# STM32H747_CM7 register map
File version: 2.3
CPU: CM7 r0p1, little endian, MPU, FPU, 4 interrupt priority bits
Registers are 32-bit, read-write, reset 0x0 unless marked. A register's access mark holds for its fields unless they carry their own. Offsets are from the block's base; [hi:lo] are bit positions; lines under a group give offsets from that group; {n}, {i} and the like mark numbered series; 'fields as' and 'values as' point back to an identical list.

## FLASH — Embedded Flash Memory
Base 0x52002000
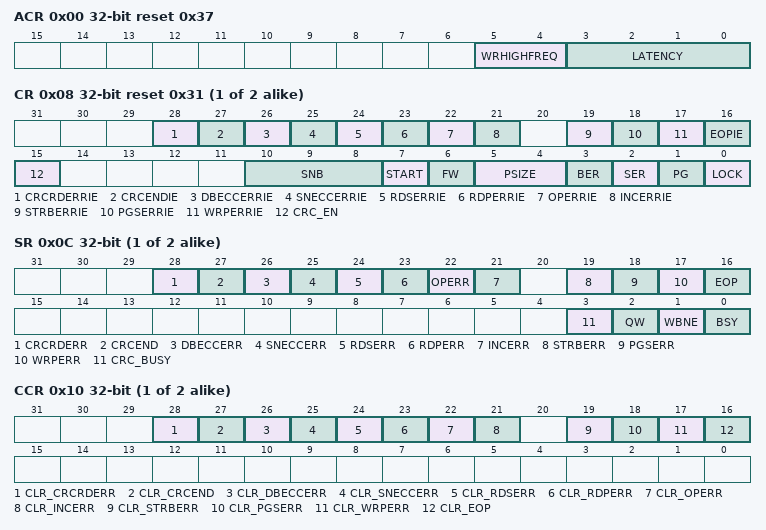
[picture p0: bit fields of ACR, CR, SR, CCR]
0x00 ACR access not given reset 0x37 — FLASH access control register
  [5:4] WRHIGHFREQ — Flash signal delay
  [3:0] LATENCY — Read latency
0x04 BANK{i} (i=1..2; step 0x100) group — Cluster BANK{i}, containing KEYR?, CR?, SR?, CCR?, PRAR_CUR?, PRAR_PRG?, SCAR_CUR?, SCAR_PRG?, WPSN_CUR?R, WPSN_PRG?R, CRCCR?, CRCSADD?R, CRCEADD?R, ECC_FA?R
  0x00 KEYR wo — FLASH key register for bank 1
    [31:0] KEY1R — Bank access configuration unlock key
  0x08 CR access not given reset 0x31 — FLASH control register for bank 1
    [28] CRCRDERRIE — Bank 1 CRC read error interrupt enable bit
    [27] CRCENDIE — Bank 1 CRC end of calculation interrupt enable bit
    [26] DBECCERRIE — Bank 1 ECC double detection error interrupt enable bit
    [25] SNECCERRIE — Bank 1 ECC single correction error interrupt enable bit
    [24] RDSERRIE — Bank 1 secure error interrupt enable bit
    [23] RDPERRIE — Bank 1 read protection error interrupt enable bit
    [22] OPERRIE — Bank 1 write
    [21] INCERRIE — Bank 1 inconsistency error interrupt enable bit
    [19] STRBERRIE — Bank 1 strobe error interrupt enable bit
    [18] PGSERRIE — Bank 1 programming sequence error interrupt enable bit
    [17] WRPERRIE — Bank 1 write protection error interrupt enable bit
    [16] EOPIE — Bank 1 end-of-program interrupt control bit
    [15] CRC_EN — Bank 1 CRC control bit
    [10:8] SNB — Bank 1 sector erase selection number
    [7] START — Bank 1 erase start control bit
    [6] FW — Bank 1 write forcing control bit
    [5:4] PSIZE — Bank 1 program size
    [3] BER — Bank 1 erase request
    [2] SER — Bank 1 sector erase request
    [1] PG — Bank 1 internal buffer control bit
    [0] LOCK — Bank 1 configuration lock bit
  0x0C SR access not given — FLASH status register for bank 1
    [28] CRCRDERR — Bank 1 CRC read error flag
    [27] CRCEND — Bank 1 CRC end of calculation flag
    [26] DBECCERR — Bank 1 ECC double detection error flag
    [25] SNECCERR — Bank 1 single correction error flag
    [24] RDSERR — Bank 1 secure error flag
    [23] RDPERR — Bank 1 read protection error flag
    [22] OPERR — Bank 1 write
    [21] INCERR — Bank 1 inconsistency error flag
    [19] STRBERR — Bank 1 strobe error flag
    [18] PGSERR — Bank 1 programming sequence error flag
    [17] WRPERR — Bank 1 write protection error flag
    [16] EOP — Bank 1 end-of-program flag
    [3] CRC_BUSY — Bank 1 CRC busy flag
    [2] QW — Bank 1 wait queue flag
    [1] WBNE — Bank 1 write buffer not empty flag
    [0] BSY — Bank 1 busy flag
  0x10 CCR access not given — FLASH clear control register for bank 1
    [28] CLR_CRCRDERR — Bank 1 CRCRDERR1 flag clear bit
    [27] CLR_CRCEND — Bank 1 CRCEND1 flag clear bit
    [26] CLR_DBECCERR — Bank 1 DBECCERR1 flag clear bit
    [25] CLR_SNECCERR — Bank 1 SNECCERR1 flag clear bit
    [24] CLR_RDSERR — Bank 1 RDSERR1 flag clear bit
    [23] CLR_RDPERR — Bank 1 RDPERR1 flag clear bit
    [22] CLR_OPERR — Bank 1 OPERR1 flag clear bit
    [21] CLR_INCERR — Bank 1 INCERR1 flag clear bit
    [19] CLR_STRBERR — Bank 1 STRBERR1 flag clear bit
    [18] CLR_PGSERR — Bank 1 PGSERR1 flag clear bit
    [17] CLR_WRPERR — Bank 1 WRPERR1 flag clear bit
    [16] CLR_EOP — Bank 1 EOP1 flag clear bit
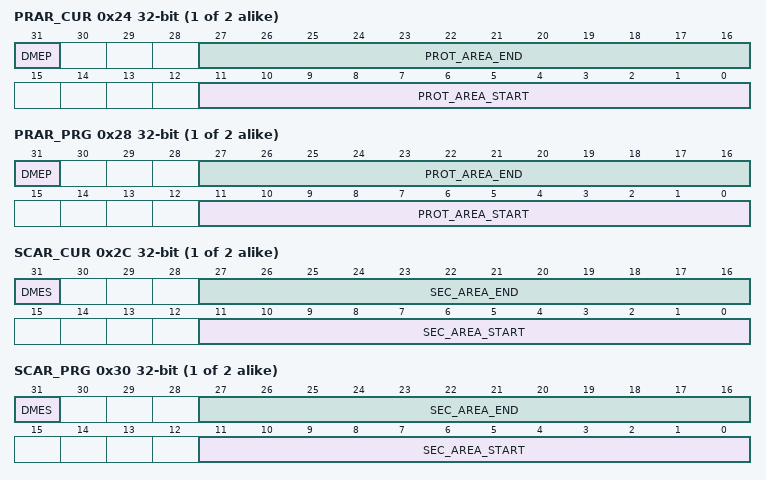
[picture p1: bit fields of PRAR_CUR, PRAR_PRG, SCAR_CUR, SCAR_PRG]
  0x24 PRAR_CUR access not given — FLASH protection address for bank 1
    [31] DMEP — Bank 1 PCROP protected erase enable option status bit
    [27:16] PROT_AREA_END — Bank 1 PCROP area end status bits
    [11:0] PROT_AREA_START — Bank 1 PCROP area start status bits
  0x28 PRAR_PRG access not given — FLASH protection address for bank 1
    [31] DMEP — Bank 1 PCROP protected erase enable option configuration bit
    [27:16] PROT_AREA_END — Bank 1 PCROP area end configuration bits
    [11:0] PROT_AREA_START — Bank 1 PCROP area start configuration bits
  0x2C SCAR_CUR access not given — FLASH secure address for bank 1
    [31] DMES — Bank 1 secure access protected erase enable option status bit
    [27:16] SEC_AREA_END — Bank 1 secure-only area end status bits
    [11:0] SEC_AREA_START — Bank 1 secure-only area start status bits
  0x30 SCAR_PRG access not given — FLASH secure address for bank 1
    [31] DMES — Bank 1 secure access protected erase enable option configuration bit
    [27:16] SEC_AREA_END — Bank 1 secure-only area end configuration bits
    [11:0] SEC_AREA_START — Bank 1 secure-only area start configuration bits
  0x34 WPSN_CURR access not given — FLASH write sector protection for bank 1
    [7:0] WRPSn — Bank 1 sector write protection option status byte
  0x38 WPSN_PRGR access not given — FLASH write sector protection for bank 1
    [7:0] WRPSn — Bank 1 sector write protection option status byte
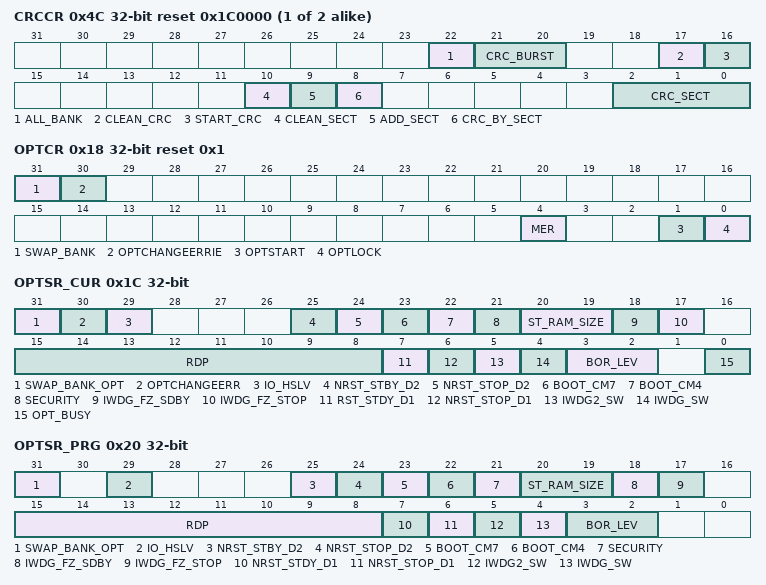
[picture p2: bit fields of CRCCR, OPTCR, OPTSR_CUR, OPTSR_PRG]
  0x4C CRCCR access not given reset 0x1C0000 — FLASH CRC control register for bank 1
    [22] ALL_BANK — Bank 1 CRC select bit
    [21:20] CRC_BURST — Bank 1 CRC burst size
    [17] CLEAN_CRC — Bank 1 CRC clear bit
    [16] START_CRC — Bank 1 CRC start bit
    [10] CLEAN_SECT — Bank 1 CRC sector list clear bit
    [9] ADD_SECT — Bank 1 CRC sector select bit
    [8] CRC_BY_SECT — Bank 1 CRC sector mode select bit
    [2:0] CRC_SECT — Bank 1 CRC sector number
  0x50 CRCSADDR access not given — FLASH CRC start address register for bank 1
    [19:2] CRC_START_ADDR — CRC start address on bank 1
  0x54 CRCEADDR access not given — FLASH CRC end address register for bank 1
    [19:2] CRC_END_ADDR — CRC end address on bank 1
  0x5C FAR access not given — FLASH ECC fail address for bank 1
    [14:0] FAIL_ECC_ADDR — Bank 1 ECC error address
0x08 OPTKEYR wo — FLASH option key register
  [31:0] OPTKEYR — FLASH option bytes control access unlock key
0x18 OPTCR access not given reset 0x1 — FLASH option control register
  [31] SWAP_BANK — Bank swapping option configuration bit
  [30] OPTCHANGEERRIE — Option byte change error interrupt enable bit
  [4] MER — mass erase request
  [1] OPTSTART — Option byte start change option configuration bit
  [0] OPTLOCK — FLASH
0x1C OPTSR_CUR access not given — FLASH option status register
  [31] SWAP_BANK_OPT — Bank swapping option status bit
  [30] OPTCHANGEERR — Option byte change error flag
  [29] IO_HSLV — I
  [25] NRST_STBY_D2 — D2 domain DStandby entry reset option status bit
  [24] NRST_STOP_D2 — D2 domain DStop entry reset option status bit
  [23] BOOT_CM7 — Arm Cortex
  [22] BOOT_CM4 — Arm Cortex
  [21] SECURITY — Security enable option status bit
  [20:19] ST_RAM_SIZE — ST RAM size option status
  [18] IWDG_FZ_SDBY — IWDG Standby mode freeze option status bit
  [17] IWDG_FZ_STOP — IWDG Stop mode freeze option status bit
  [15:8] RDP — Readout protection level option status byte
  [7] RST_STDY_D1 — D1 domain DStandby entry reset option status bit
  [6] NRST_STOP_D1 — D1 domain DStop entry reset option status bit
  [5] IWDG2_SW — IWDG2 control mode option status bit
  [4] IWDG_SW — IWDG control mode option status bit
  [3:2] BOR_LEV — Brownout level option status bit
  [0] OPT_BUSY — Option byte change ongoing flag
0x20 OPTSR_PRG access not given — FLASH option status register
  [31] SWAP_BANK_OPT — Bank swapping option configuration bit
  [29] IO_HSLV — I
  [25] NRST_STBY_D2 — D2 domain DStandby entry reset option configuration bit
  [24] NRST_STOP_D2 — D2 domain DStop entry reset option configuration bit
  [23] BOOT_CM7 — Arm Cortex
  [22] BOOT_CM4 — Arm Cortex
  [21] SECURITY — Security enable option configuration bit
  [20:19] ST_RAM_SIZE — ST RAM size option configuration bits
  [18] IWDG_FZ_SDBY — IWDG Standby mode freeze option configuration bit
  [17] IWDG_FZ_STOP — IWDG Stop mode freeze option configuration bit
  [15:8] RDP — Readout protection level option configuration bits
  [7] NRST_STDY_D1 — D1 domain DStandby entry reset option configuration bit
  [6] NRST_STOP_D1 — D1 domain DStop entry reset option configuration bit
  [5] IWDG2_SW — IWDG2 control mode option configuration bit
  [4] IWDG_SW — IWDG control mode option configuration bit
  [3:2] BOR_LEV — Brownout level option configuration bit
0x24 OPTCCR access not given — FLASH option clear control register
  [30] CLR_OPTCHANGEERR — OPTCHANGEERR reset bit
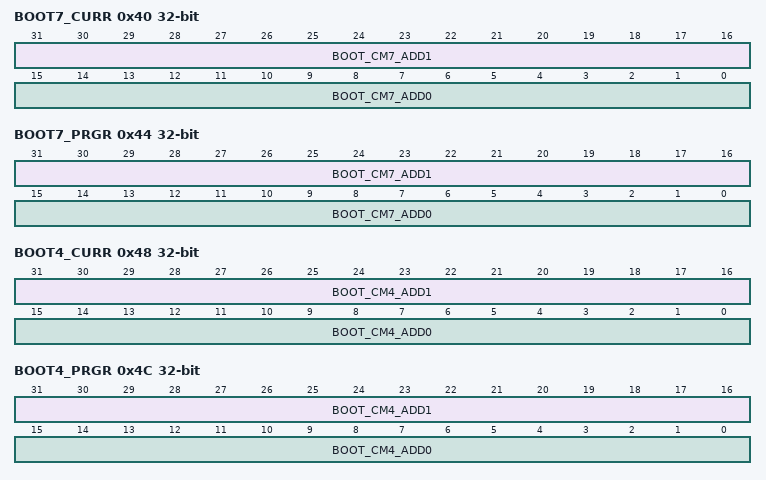
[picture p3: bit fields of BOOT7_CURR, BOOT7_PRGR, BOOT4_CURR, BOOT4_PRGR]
0x40 BOOT7_CURR access not given — FLASH register boot address for Arm Cortex-M7 core
  [31:16] BOOT_CM7_ADD1 — Arm Cortex-M7 boot address 1
  [15:0] BOOT_CM7_ADD0 — Arm Cortex-M7 boot address 0
0x44 BOOT7_PRGR access not given — FLASH register boot address for Arm Cortex-M7 core
  [31:16] BOOT_CM7_ADD1 — Arm Cortex-M7 boot address 1 configuration
  [15:0] BOOT_CM7_ADD0 — Arm Cortex-M7 boot address 0 configuration
0x48 BOOT4_CURR access not given — FLASH register boot address for Arm Cortex-M4 core
  [31:16] BOOT_CM4_ADD1 — Arm Cortex-M4 boot address 1
  [15:0] BOOT_CM4_ADD0 — Arm Cortex-M4 boot address 0
0x4C BOOT4_PRGR access not given — FLASH register boot address for Arm Cortex-M4 core
  [31:16] BOOT_CM4_ADD1 — Arm Cortex-M4 boot address 1 configuration
  [15:0] BOOT_CM4_ADD0 — Arm Cortex-M4 boot address 0 configuration
0x5C CRCDATAR access not given — FLASH CRC data register
  [31:0] CRC_DATA — CRC result
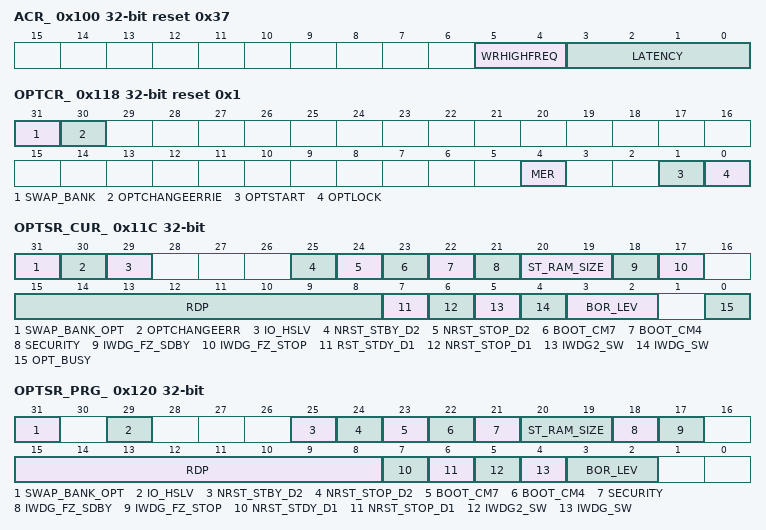
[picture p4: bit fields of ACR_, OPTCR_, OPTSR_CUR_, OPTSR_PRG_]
0x100 ACR_ access not given reset 0x37 — FLASH access control register
  [5:4] WRHIGHFREQ — Flash signal delay
  [3:0] LATENCY — Read latency
0x108 OPTKEYR_ wo — FLASH option key register
  [31:0] OPTKEYR — FLASH option bytes control access unlock key
0x118 OPTCR_ access not given reset 0x1 — FLASH option control register
  fields as OPTCR
0x11C OPTSR_CUR_ access not given — FLASH option status register
  fields as OPTSR_CUR
0x120 OPTSR_PRG_ access not given — FLASH option status register
  fields as OPTSR_PRG
0x124 OPTCCR_ access not given — FLASH option clear control register
  [30] CLR_OPTCHANGEERR — OPTCHANGEERR reset bit
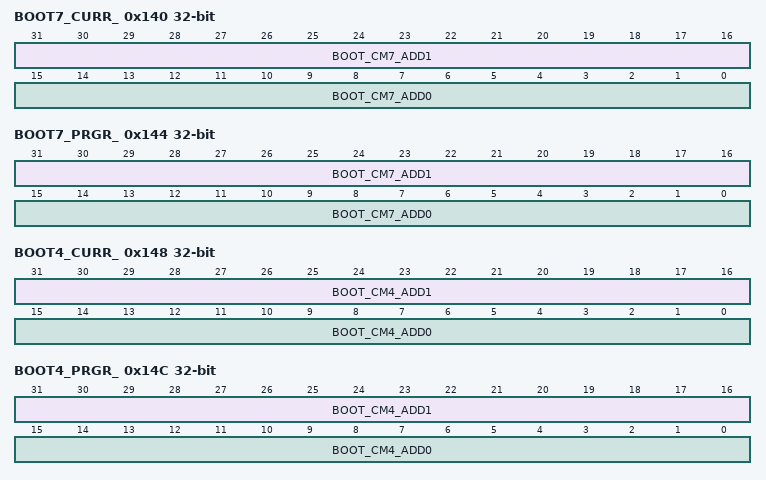
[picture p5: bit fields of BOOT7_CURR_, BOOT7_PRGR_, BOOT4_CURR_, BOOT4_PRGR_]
0x140 BOOT7_CURR_ access not given — FLASH register boot address for Arm Cortex-M7 core
  fields as BOOT7_CURR
0x144 BOOT7_PRGR_ access not given — FLASH register boot address for Arm Cortex-M7 core
  fields as BOOT7_PRGR
0x148 BOOT4_CURR_ access not given — FLASH register boot address for Arm Cortex-M4 core
  fields as BOOT4_CURR
0x14C BOOT4_PRGR_ access not given — FLASH register boot address for Arm Cortex-M4 core
  fields as BOOT4_PRGR
